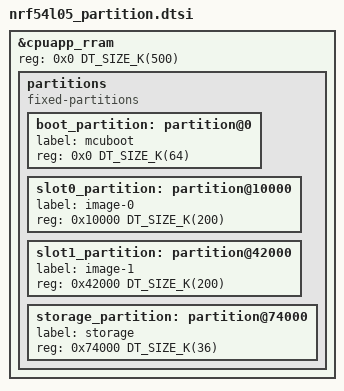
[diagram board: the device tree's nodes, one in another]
/*
 * Copyright (c) 2025 Nordic Semiconductor ASA
 *
 * SPDX-License-Identifier: Apache-2.0
 */

&cpuapp_rram {
	reg = <0x0 DT_SIZE_K(500)>;
};

/* These partition sizes assume no FLPR area in RRAM */
&cpuapp_rram {
	partitions {
		compatible = "fixed-partitions";
		#address-cells = <1>;
		#size-cells = <1>;

		boot_partition: partition@0 {
			label = "mcuboot";
			reg = <0x0 DT_SIZE_K(64)>;
		};

		slot0_partition: partition@10000 {
			label = "image-0";
			reg = <0x10000 DT_SIZE_K(200)>;
		};

		slot1_partition: partition@42000 {
			label = "image-1";
			reg = <0x42000 DT_SIZE_K(200)>;
		};

		storage_partition: partition@74000 {
			label = "storage";
			reg = <0x74000 DT_SIZE_K(36)>;
		};
	};
};
